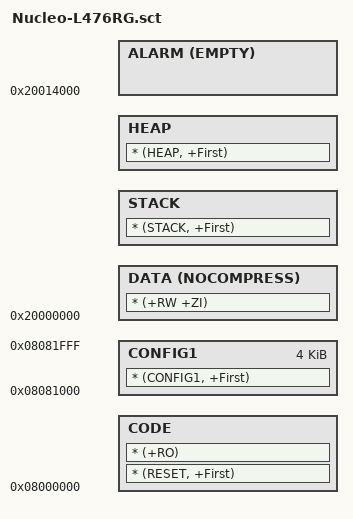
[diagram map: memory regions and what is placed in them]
FLASH 0x8000000 0x80000
{
    CODE 0x8000000 {
        * (RESET, +First)            ; +First means that this section is never marked unused
        * (+RO)
    }
;    OPS +0x0 ALIGN 16 {
;        * (.ops)
;    }
    DATA 0x20000000 NOCOMPRESS {
        * (+RW +ZI)
    }
    STACK +0x0 {
        * (STACK, +First)
    }
    HEAP +0x0 {
        * (HEAP, +First)
    }
    ALARM 0x20014000 EMPTY 0 {       ; Segment to check if RAM placed data overflows RAM
    }
}
CONFIG1 0x08081000 0x01000
{
    CONFIG1 0x08081000 0x1000 {
        * (CONFIG1, +First)
    }
}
